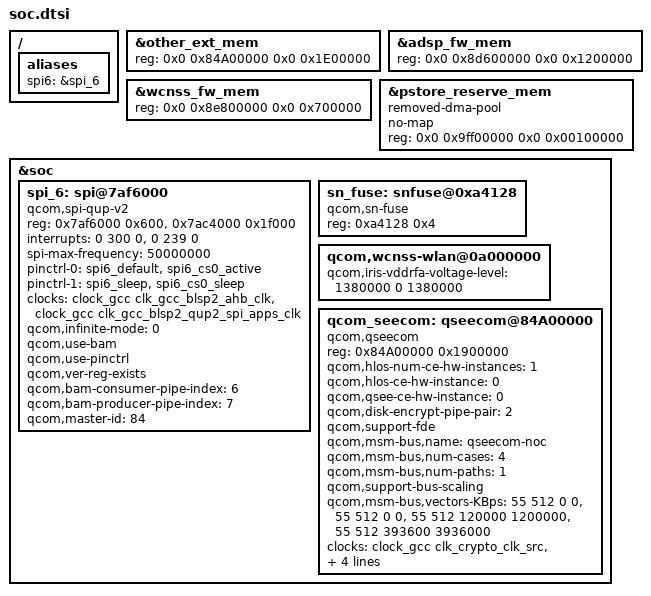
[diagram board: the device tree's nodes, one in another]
/* msm8953.dtsi */
&other_ext_mem {
	reg = <0x0 0x84A00000 0x0 0x1E00000>;
};
&adsp_fw_mem {
	reg = <0x0 0x8d600000 0x0 0x1200000>;
};
&wcnss_fw_mem {
	reg = <0x0 0x8e800000 0x0 0x700000>;
};
&pstore_reserve_mem {
    compatible = "removed-dma-pool";
	no-map;
	reg = <0x0 0x9ff00000 0x0 0x00100000>;
}

/ {
	aliases {
		spi6 = &spi_6;
	};
};

&soc {
        spi_6: spi@7af6000 { /* BLSP2 QUP2 */
		compatible = "qcom,spi-qup-v2";
		#address-cells = <1>;
		#size-cells = <0>;
		reg-names = "spi_physical", "spi_bam_physical";
		reg = <0x7af6000 0x600>,
			<0x7ac4000 0x1f000>;
		interrupt-names = "spi_irq", "spi_bam_irq";
		interrupts = <0 300 0>, <0 239 0>;
		spi-max-frequency = <50000000>;
		pinctrl-names = "spi_default", "spi_sleep";
		pinctrl-0 = <&spi6_default &spi6_cs0_active>;
		pinctrl-1 = <&spi6_sleep &spi6_cs0_sleep>;
		clocks = <&clock_gcc clk_gcc_blsp2_ahb_clk>,
			<&clock_gcc clk_gcc_blsp2_qup2_spi_apps_clk>;
		clock-names = "iface_clk", "core_clk";
		qcom,infinite-mode = <0>;
		qcom,use-bam;
		qcom,use-pinctrl;
		qcom,ver-reg-exists;
		qcom,bam-consumer-pipe-index = <6>;
		qcom,bam-producer-pipe-index = <7>;
		qcom,master-id = <84>;
	};

    sn_fuse: snfuse@0xa4128 {
		compatible = "qcom,sn-fuse";
		reg = <0xa4128 0x4>;
		reg-names = "sn-base";
	};

    qcom,wcnss-wlan@0a000000 {
		qcom,iris-vddrfa-voltage-level = <1380000 0 1380000>;
	};

    /delete-node/ qseecom@85b00000;
	qcom_seecom: qseecom@84A00000 {
		compatible = "qcom,qseecom";
		reg = <0x84A00000 0x1900000>;
		reg-names = "secapp-region";
		qcom,hlos-num-ce-hw-instances = <1>;
		qcom,hlos-ce-hw-instance = <0>;
		qcom,qsee-ce-hw-instance = <0>;
		qcom,disk-encrypt-pipe-pair = <2>;
		qcom,support-fde;
		qcom,msm-bus,name = "qseecom-noc";
		qcom,msm-bus,num-cases = <4>;
		qcom,msm-bus,num-paths = <1>;
		qcom,support-bus-scaling;
		qcom,msm-bus,vectors-KBps =
			<55 512 0 0>,
			<55 512 0 0>,
			<55 512 120000 1200000>,
			<55 512 393600 3936000>;
		clocks = <&clock_gcc clk_crypto_clk_src>,
			 <&clock_gcc clk_gcc_crypto_clk>,
			 <&clock_gcc clk_gcc_crypto_ahb_clk>,
			 <&clock_gcc clk_gcc_crypto_axi_clk>;
		clock-names = "core_clk_src", "core_clk",
				"iface_clk", "bus_clk";
		qcom,ce-opp-freq = <100000000>;
	};
};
